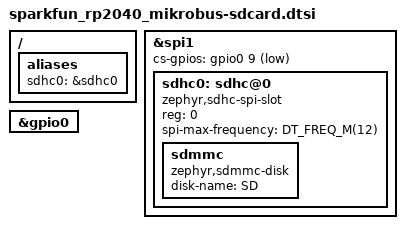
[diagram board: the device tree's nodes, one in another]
/*
 * SPDX-FileCopyrightText: Copyright (c) 2026 Navimatix GmbH
 * SPDX-FileCopyrightText: Copyright (c) 2026 TiaC Systems
 * SPDX-License-Identifier: Apache-2.0
 */

#include <freq.h>
#include <zephyr/dt-bindings/gpio/gpio.h>

/ {
	aliases {
		sdhc0 = &sdhc0;
	};
};

&spi1 {
	cs-gpios = <&gpio0 9 GPIO_ACTIVE_LOW>;
	status = "okay";

	sdhc0: sdhc@0 {
		compatible = "zephyr,sdhc-spi-slot";
		reg = <0>;

		spi-max-frequency = <DT_FREQ_M(12)>;
		status = "okay";

		sdmmc {
			compatible = "zephyr,sdmmc-disk";

			disk-name = "SD";
			status = "okay";
		};
	};
};

&gpio0 {
	status = "okay";
};
